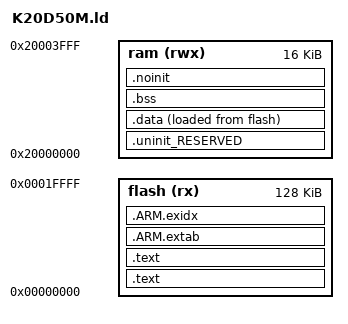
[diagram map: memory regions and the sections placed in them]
/*------------------------------------------------------------------------------
 *      Linker script for running in EBI DDR on the SAMA5-MIURA
 *----------------------------------------------------------------------------*/

OUTPUT_FORMAT("elf32-littlearm", "elf32-littlearm", "elf32-littlearm")
OUTPUT_ARCH(arm)
ENTRY(ResetISR)
SEARCH_DIR(.)

STACK_SIZE = 0x500;
HEAP_SIZE  = 0x500;

/* Memory Spaces Definitions */
/* Linker script to configure memory regions. */
MEMORY
{
  /* Define each memory region */
  flash (rx)  : ORIGIN = 0x0,       LENGTH = 0x20000 /* 128K bytes (alias Flash) */  
  ram   (rwx) : ORIGIN = 0x20000000, LENGTH = 0x4000  /* 16K  bytes (alias RAM) */  
}

SECTIONS
{
    /* MAIN TEXT SECTION */
    .text : ALIGN(4)
    {
        FILL(0xff)
        __vectors_start__ = ABSOLUTE(.) ;
        KEEP(*(.isr_vector))
        
        /* Flash Security */
        . = ALIGN(0x400);
        KEEP(*(.flash_security))
        
        /* Global Section Table */
        . = ALIGN(0x500);
        __section_table_start = .;
        
        __data_section_table = .;
        LONG(LOADADDR(.data));
        LONG(    ADDR(.data));
        LONG(  SIZEOF(.data));
        __data_section_table_end = .;
        
        __bss_section_table = .;
        LONG(    ADDR(.bss));
        LONG(  SIZEOF(.bss));
        __bss_section_table_end = .;
        __section_table_end = . ;
        
	    /* End of Global Section Table */

        *(.after_vectors*)

    } >flash

    .text : ALIGN(4)    
    {
        *(.text*)
        *(.rodata .rodata.* .constdata .constdata.*)
        . = ALIGN(4);
    } > flash
    /*
     * for exception handling/unwind - some Newlib functions (in common
     * with C++ and STDC++) use this. 
     */
    .ARM.extab : ALIGN(4) 
    {
        *(.ARM.extab* .gnu.linkonce.armextab.*)
    } > flash
    __exidx_start = .;

    .ARM.exidx : ALIGN(4)
    {
        *(.ARM.exidx* .gnu.linkonce.armexidx.*)
    } > flash
    __exidx_end = .;

    _etext = .;
        
    /* MAIN DATA SECTION */
    .uninit_RESERVED : ALIGN(4)
    {
        KEEP(*(.bss.$RESERVED*))
        . = ALIGN(4) ;
        _end_uninit_RESERVED = .;
    } > ram
    
    /* Main DATA section (ram) */
    .data : ALIGN(4)
    {
       FILL(0xff)
       _data = . ;
       *(vtable)
       *(.ramfunc*)
       *(.data*)
       . = ALIGN(4) ;
       _edata = . ;
    } > ram AT>flash
    
    /* MAIN BSS SECTION */
    .bss : ALIGN(4)
    {
        _bss = .;
        *(.bss*)
        *(COMMON)
        . = ALIGN(4) ;
        _ebss = .;
        PROVIDE(end = .);
    } > ram
    
    /* DEFAULT NOINIT SECTION */
    .noinit (NOLOAD): ALIGN(4)
    {
        _noinit = .;
        *(.noinit*) 
        . = ALIGN(4) ;
        PROVIDE(_vStackTop = . + STACK_SIZE);
        PROVIDE(_pvHeapStart = _vStackTop + HEAP_SIZE);
        _end_noinit = .;
    } > ram

  /* Stabs debugging sections.  */
  .stab 0 : { *(.stab) }
  .stabstr 0 : { *(.stabstr) }
  .stab.excl 0 : { *(.stab.excl) }
  .stab.exclstr 0 : { *(.stab.exclstr) }
  .stab.index 0 : { *(.stab.index) }
  .stab.indexstr 0 : { *(.stab.indexstr) }
  .comment 0 : { *(.comment) }
  /* DWARF debug sections.
     Symbols in the DWARF debugging sections are relative to the beginning
     of the section so we begin them at 0.  */
  /* DWARF 1 */
  .debug          0 : { *(.debug) }
  .line           0 : { *(.line) }
  /* GNU DWARF 1 extensions */
  .debug_srcinfo  0 : { *(.debug_srcinfo) }
  .debug_sfnames  0 : { *(.debug_sfnames) }
  /* DWARF 1.1 and DWARF 2 */
  .debug_aranges  0 : { *(.debug_aranges) }
  .debug_pubnames 0 : { *(.debug_pubnames) }
  /* DWARF 2 */
  .debug_info     0 : { *(.debug_info) }
  .debug_abbrev   0 : { *(.debug_abbrev) }
  .debug_line     0 : { *(.debug_line) }
  .debug_frame    0 : { *(.debug_frame) }
  .debug_str      0 : { *(.debug_str) }
  .debug_loc      0 : { *(.debug_loc) }
  .debug_macinfo  0 : { *(.debug_macinfo) }
  /* SGI/MIPS DWARF 2 extensions */
  .debug_weaknames 0 : { *(.debug_weaknames) }
  .debug_funcnames 0 : { *(.debug_funcnames) }
  .debug_typenames 0 : { *(.debug_typenames) }
  .debug_varnames  0 : { *(.debug_varnames) }

  /* These must appear regardless of  .  */
}
